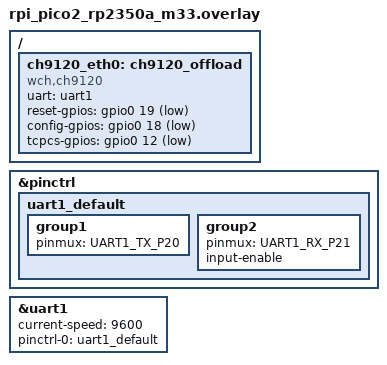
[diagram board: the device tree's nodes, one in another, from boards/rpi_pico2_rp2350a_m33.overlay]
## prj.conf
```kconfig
# Enable networking
CONFIG_NETWORKING=y
CONFIG_NET_SOCKETS=y
CONFIG_NET_SOCKETS_OFFLOAD=y
CONFIG_NET_L2_ETHERNET=y

# Your driver
CONFIG_ETH_CH9120=y

# Disable LwIP — CH9120 owns TCP/IP
CONFIG_NET_IPV4=n
CONFIG_NET_IPV6=n
CONFIG_NET_TCP=n
CONFIG_NET_UDP=n

# UART
CONFIG_UART_INTERRUPT_DRIVEN=y

# GPIO
CONFIG_GPIO=y

# Zephyr test framework
CONFIG_ZTEST=y

# Logging — essential during bring up
CONFIG_LOG=y
CONFIG_LOG_DEFAULT_LEVEL=4

# Stack sizes — networking needs more than default
CONFIG_MAIN_STACK_SIZE=2048
CONFIG_SYSTEM_WORKQUEUE_STACK_SIZE=2048
```

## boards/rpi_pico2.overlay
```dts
/* boards/rpi_pico2.overlay */

&uart1 {
    status = "okay";
    current-speed = <9600>;
    pinctrl-0 = <&uart1_default>;
    pinctrl-names = "default";
};

/ {
    ch9120_eth0: ch9120_offload {
        compatible = "wch,ch9120";
        uart = <&uart1>;

        reset-gpios = <&gpio0 19 GPIO_ACTIVE_LOW>;
        config-gpios = <&gpio0 18 GPIO_ACTIVE_LOW>;
        tcpcs-gpios = <&gpio0 12 GPIO_ACTIVE_LOW>;

        status = "okay";
    };
};
```

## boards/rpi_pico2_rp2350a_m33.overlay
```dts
/* boards/rpi_pico2.overlay */

&pinctrl {
    uart1_default: uart1_default {
        group1 {
            pinmux = <UART1_TX_P20>;
        };
        group2 {
            pinmux = <UART1_RX_P21>;
            input-enable;
        };
    };
};

&uart1 {
    status = "okay";
    current-speed = <9600>;
    pinctrl-0 = <&uart1_default>;
    pinctrl-names = "default";
};

/ {
    ch9120_eth0: ch9120_offload {
        compatible = "wch,ch9120";
        uart = <&uart1>;

        reset-gpios = <&gpio0 19 GPIO_ACTIVE_LOW>;
        config-gpios = <&gpio0 18 GPIO_ACTIVE_LOW>;
        tcpcs-gpios = <&gpio0 12 GPIO_ACTIVE_LOW>;

        status = "okay";
    };
};
```

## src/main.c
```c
#include <zephyr/ztest.h>
#include <zephyr/device.h>
#include <zephyr/net/net_if.h>

ZTEST(ch9120_init, test_device_ready)
{
    const struct device *dev = DEVICE_DT_GET(DT_NODELABEL(ch9120_eth0));

    zassert_not_null(dev, "CH9120 device not found in devicetree");
    zassert_true(device_is_ready(dev), "CH9120 device not ready");
}

ZTEST(ch9120_init, test_net_if_exists)
{
    struct net_if *iface = net_if_get_default();

    zassert_not_null(iface, "No default network interface found");
}

ZTEST_SUITE(ch9120_init, NULL, NULL, NULL, NULL, NULL);
```
